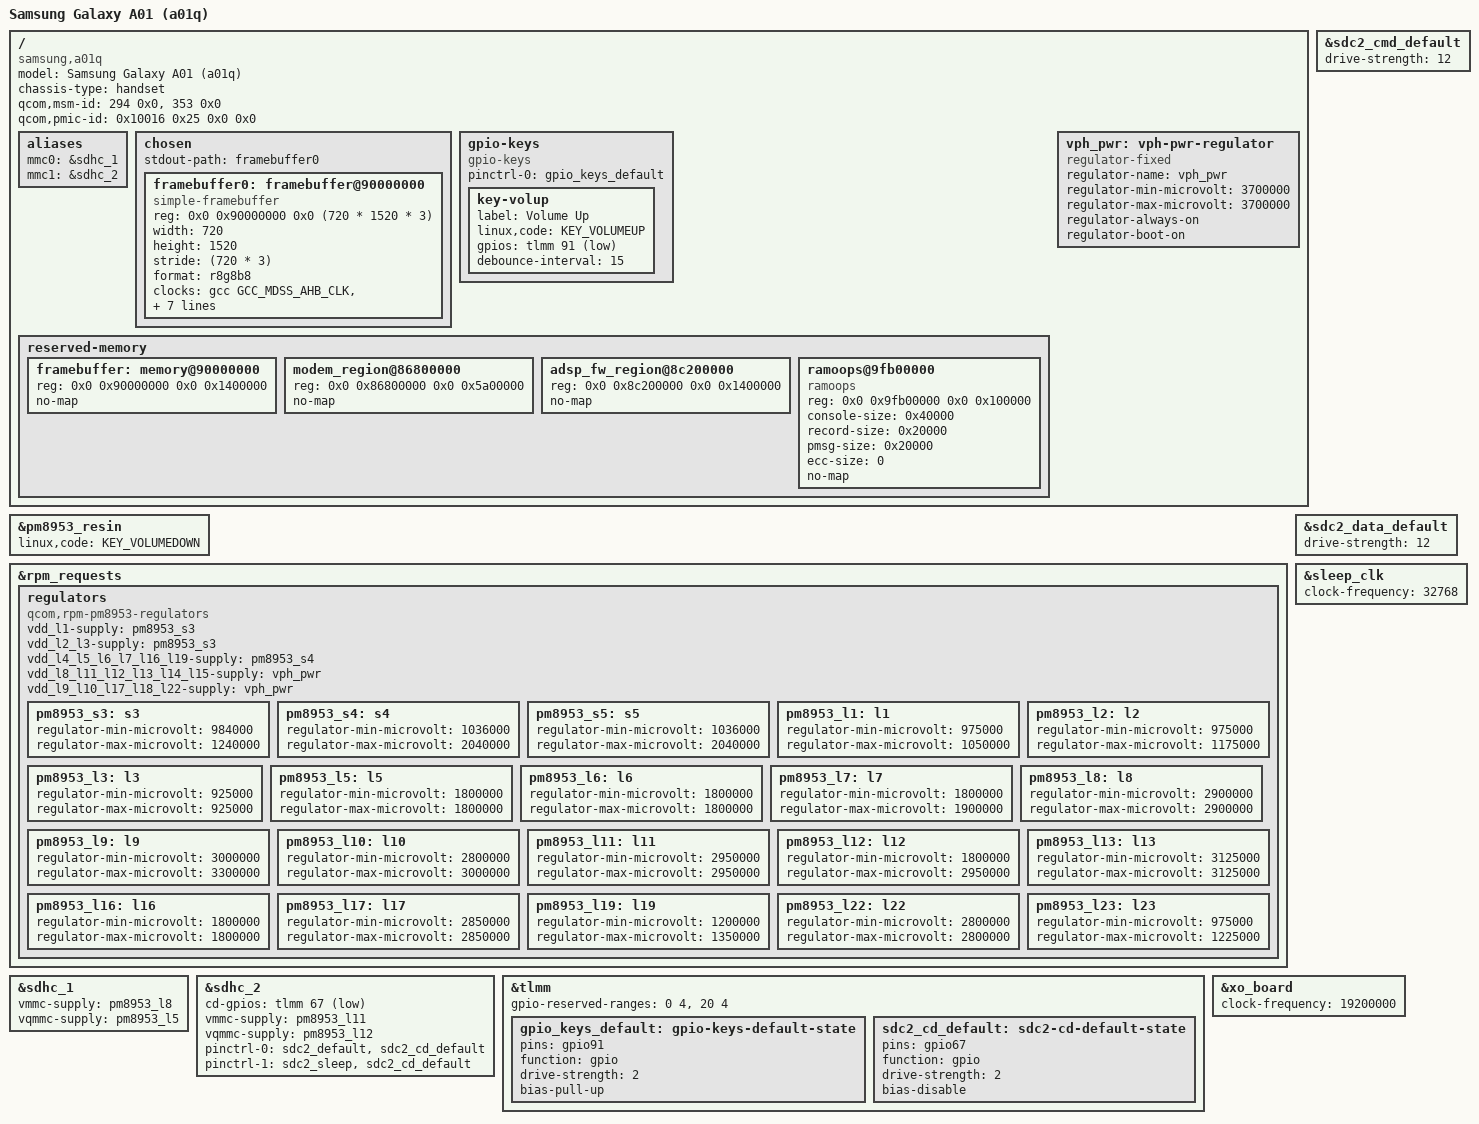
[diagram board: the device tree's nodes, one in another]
// SPDX-License-Identifier: BSD-3-Clause
/*
 * Samsung Galaxy A01 (SM-A015*, codename a01q), regular Brazilian variant.
 *
 * Milestone 1: boot to userspace with framebuffer, eMMC/SD, buttons, pstore,
 * touchscreen and Wi-Fi (see msm8937-samsung-a01q-touch-wifi.dtsi).
 * Deliberately NOT enabled yet: USB, GPU, panel, charger/fuel gauge, audio,
 * camera, cpufreq.
 *
 * Derived from msm8937-xiaomi-land.dts and sdm632-fairphone-fp3.dts.
 */
/dts-v1/;

#include <dt-bindings/gpio/gpio.h>
#include <dt-bindings/input/linux-event-codes.h>

#include "msm8937.dtsi"
#include "pm8953.dtsi"
#include "pmi632.dtsi"

/ {
	model = "Samsung Galaxy A01 (a01q)";
	compatible = "samsung,a01q", "qcom,msm8937";
	chassis-type = "handset";

	/*
	 * The stock boot.img carries two base DTBs and selects one by chip and
	 * PMIC id only (the base DTBs have no qcom,board-id property):
	 *   0x126 (294): "MSM8953 + PMI632"
	 *   0x161 (353): "SDM439 MTP"   <-- the Galaxy A01 (SDM439)
	 * Which of the two a given unit selects is not confirmed, so list both
	 * chip ids (the bootloader matches any entry). Do not add a board-id.
	 */
	qcom,msm-id = <294 0x0>, <353 0x0>;
	qcom,pmic-id = <0x10016 0x25 0x0 0x0>;

	aliases {
		mmc0 = &sdhc_1;
		mmc1 = &sdhc_2;
	};

	chosen {
		#address-cells = <2>;
		#size-cells = <2>;
		ranges;

		stdout-path = "framebuffer0";

		/*
		 * Splash framebuffer set up by the bootloader.
		 * Pixel format: a8r8g8b8 (stride 720 * 4) produced a tiled, striped image
		 * on hardware, so the LK framebuffer is assumed to be r8g8b8 (stride 720 * 3).
		 * If the colors are swapped or the picture is still wrong, try b8g8r8.
		 */
		framebuffer0: framebuffer@90000000 {
			compatible = "simple-framebuffer";
			reg = <0x0 0x90000000 0x0 (720 * 1520 * 3)>;
			width = <720>;
			height = <1520>;
			stride = <(720 * 3)>;
			format = "r8g8b8";

			clocks = <&gcc GCC_MDSS_AHB_CLK>,
				 <&gcc GCC_MDSS_AXI_CLK>,
				 <&gcc GCC_MDSS_VSYNC_CLK>,
				 <&gcc GCC_MDSS_MDP_CLK>,
				 <&gcc GCC_MDSS_BYTE0_CLK>,
				 <&gcc GCC_MDSS_PCLK0_CLK>,
				 <&gcc GCC_MDSS_ESC0_CLK>;
			power-domains = <&gcc MDSS_GDSC>;
		};
	};

	gpio-keys {
		compatible = "gpio-keys";

		pinctrl-0 = <&gpio_keys_default>;
		pinctrl-names = "default";

		key-volup {
			label = "Volume Up";
			linux,code = <KEY_VOLUMEUP>;
			gpios = <&tlmm 91 GPIO_ACTIVE_LOW>;
			debounce-interval = <15>;
		};
	};

	reserved-memory {
		/* Stock reserves 20 MB for the bootloader splash at this address. */
		framebuffer: memory@90000000 {
			reg = <0x0 0x90000000 0x0 0x1400000>;
			no-map;
		};

		/*
		 * Firmware regions of the stock SDM439 layout (base DTB #1). The
		 * modem and ADSP are not started yet, but their memory is kept out of
		 * the kernel's hands exactly like the stock kernel does. The WCNSS
		 * region (0x8d600000, 7 MB) follows right after, see the touch/wifi dtsi.
		 */
		modem_region@86800000 {
			reg = <0x0 0x86800000 0x0 0x5a00000>;
			no-map;
		};

		adsp_fw_region@8c200000 {
			reg = <0x0 0x8c200000 0x0 0x1400000>;
			no-map;
		};

		/* Same location the stock kernel uses; survives warm reboots. */
		ramoops@9fb00000 {
			compatible = "ramoops";
			reg = <0x0 0x9fb00000 0x0 0x100000>;
			console-size = <0x40000>;
			record-size = <0x20000>;
			pmsg-size = <0x20000>;
			ecc-size = <0>;
			no-map;
		};
	};

	vph_pwr: vph-pwr-regulator {
		compatible = "regulator-fixed";
		regulator-name = "vph_pwr";
		regulator-min-microvolt = <3700000>;
		regulator-max-microvolt = <3700000>;
		regulator-always-on;
		regulator-boot-on;
	};
};

&pm8953_resin {
	linux,code = <KEY_VOLUMEDOWN>;

	status = "okay";
};

&rpm_requests {
	regulators {
		compatible = "qcom,rpm-pm8953-regulators";

		vdd_l1-supply = <&pm8953_s3>;
		vdd_l2_l3-supply = <&pm8953_s3>;
		vdd_l4_l5_l6_l7_l16_l19-supply = <&pm8953_s4>;
		vdd_l8_l11_l12_l13_l14_l15-supply = <&vph_pwr>;
		vdd_l9_l10_l17_l18_l22-supply = <&vph_pwr>;

		pm8953_s3: s3 {
			regulator-min-microvolt = <984000>;
			regulator-max-microvolt = <1240000>;
		};

		pm8953_s4: s4 {
			regulator-min-microvolt = <1036000>;
			regulator-max-microvolt = <2040000>;
		};

		pm8953_s5: s5 {
			regulator-min-microvolt = <1036000>;
			regulator-max-microvolt = <2040000>;
		};

		pm8953_l1: l1 {
			regulator-min-microvolt = <975000>;
			regulator-max-microvolt = <1050000>;
		};

		pm8953_l2: l2 {
			regulator-min-microvolt = <975000>;
			regulator-max-microvolt = <1175000>;
		};

		pm8953_l3: l3 {
			regulator-min-microvolt = <925000>;
			regulator-max-microvolt = <925000>;
		};

		pm8953_l5: l5 {
			regulator-min-microvolt = <1800000>;
			regulator-max-microvolt = <1800000>;
		};

		pm8953_l6: l6 {
			regulator-min-microvolt = <1800000>;
			regulator-max-microvolt = <1800000>;
		};

		pm8953_l7: l7 {
			regulator-min-microvolt = <1800000>;
			regulator-max-microvolt = <1900000>;
		};

		pm8953_l8: l8 {
			regulator-min-microvolt = <2900000>;
			regulator-max-microvolt = <2900000>;
		};

		pm8953_l9: l9 {
			regulator-min-microvolt = <3000000>;
			regulator-max-microvolt = <3300000>;
		};

		pm8953_l10: l10 {
			regulator-min-microvolt = <2800000>;
			regulator-max-microvolt = <3000000>;
		};

		pm8953_l11: l11 {
			regulator-min-microvolt = <2950000>;
			regulator-max-microvolt = <2950000>;
		};

		pm8953_l12: l12 {
			regulator-min-microvolt = <1800000>;
			regulator-max-microvolt = <2950000>;
		};

		pm8953_l13: l13 {
			regulator-min-microvolt = <3125000>;
			regulator-max-microvolt = <3125000>;
		};

		pm8953_l16: l16 {
			regulator-min-microvolt = <1800000>;
			regulator-max-microvolt = <1800000>;
		};

		pm8953_l17: l17 {
			regulator-min-microvolt = <2850000>;
			regulator-max-microvolt = <2850000>;
		};

		pm8953_l19: l19 {
			regulator-min-microvolt = <1200000>;
			regulator-max-microvolt = <1350000>;
		};

		pm8953_l22: l22 {
			regulator-min-microvolt = <2800000>;
			regulator-max-microvolt = <2800000>;
		};

		pm8953_l23: l23 {
			regulator-min-microvolt = <975000>;
			regulator-max-microvolt = <1225000>;
		};
	};
};

&sdc2_cmd_default {
	drive-strength = <12>;
};

&sdc2_data_default {
	drive-strength = <12>;
};

&sdhc_1 {
	vmmc-supply = <&pm8953_l8>;
	vqmmc-supply = <&pm8953_l5>;

	status = "okay";
};

&sdhc_2 {
	cd-gpios = <&tlmm 67 GPIO_ACTIVE_LOW>;
	vmmc-supply = <&pm8953_l11>;
	vqmmc-supply = <&pm8953_l12>;
	pinctrl-0 = <&sdc2_default &sdc2_cd_default>;
	pinctrl-1 = <&sdc2_sleep &sdc2_cd_default>;
	pinctrl-names = "default", "sleep";

	status = "okay";
};

&sleep_clk {
	clock-frequency = <32768>;
};

&tlmm {
	gpio-reserved-ranges = <0 4>, <20 4>;

	gpio_keys_default: gpio-keys-default-state {
		pins = "gpio91";
		function = "gpio";
		drive-strength = <2>;
		bias-pull-up;
	};

	sdc2_cd_default: sdc2-cd-default-state {
		pins = "gpio67";
		function = "gpio";
		drive-strength = <2>;
		bias-disable;
	};
};

&xo_board {
	clock-frequency = <19200000>;
};

#include "msm8937-samsung-a01q-touch-wifi.dtsi"
